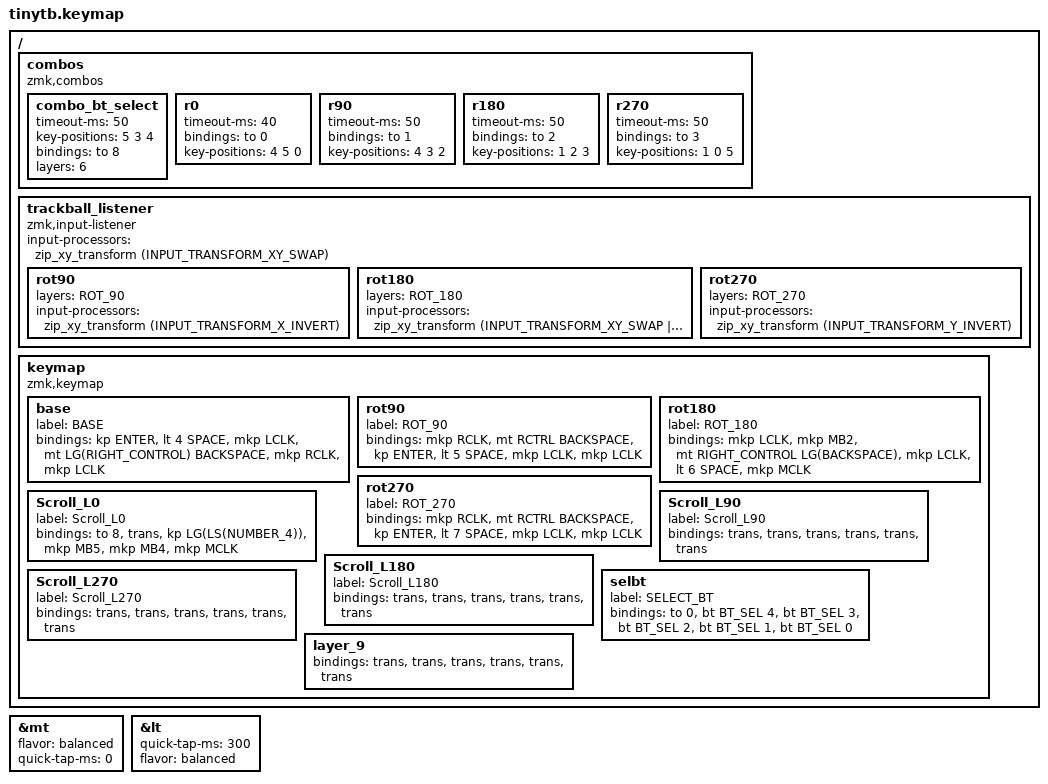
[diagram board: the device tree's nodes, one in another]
#include <input/processors.dtsi>
#include <dt-bindings/zmk/input_transform.h>
#include <zephyr/dt-bindings/input/input-event-codes.h>
#include <dt-bindings/zmk/behaviors.h>
#include <behaviors.dtsi>
#include <dt-bindings/zmk/bt.h>
#include <dt-bindings/zmk/keys.h>
#include <dt-bindings/zmk/pointing.h>

#define SCROLL 1

/* どこかの共通ヘッダの近くに */

#define BASE        0
#define ROT_90      1
#define ROT_180     2
#define ROT_270     3
#define Scroll_L0   4
#define Scroll_L90  5
#define Scroll_L180 6
#define Scroll_L270 7
#define SELECT_BT   8     /* BT設定レイヤー */

&mt {
    flavor = "balanced";
    quick-tap-ms = <0>;
};

&lt {
    quick-tap-ms = <300>;
    flavor = "balanced";
};

/ {
    /* --- コンボ定義 --- */

    combos {
        compatible = "zmk,combos";

        /* 同時押しで 設定レイヤーを開閉（トグル） */

        combo_bt_select {
            timeout-ms = <50>;              /* 反応が鈍ければ少し上げる(例: 60〜80) */
            key-positions = <5 3 4>;        /* ← ここは “1/2/3 キーの物理位置” */
            bindings = <&to 8>;   /* 入る/出るをトグル */
            /* 必要なら layers = <BASE L1 L2>; を付けて適用範囲を絞る */

            layers = <6>;
        };

        r0 {
            timeout-ms = <40>;
            bindings = <&to 0>;
            key-positions = <4 5 0>;
        };

        r90 {
            timeout-ms = <50>;              /* 反応が鈍ければ少し上げる(例: 60〜80) */
            bindings = <&to 1>;
            key-positions = <4 3 2>;
        };

        r180 {
            timeout-ms = <50>;              /* 反応が鈍ければ少し上げる(例: 60〜80) */
            bindings = <&to 2>;     /* ★1秒ホールドで 180 へ */
            key-positions = <1 2 3>;
        };

        r270 {
            timeout-ms = <50>;              /* 反応が鈍ければ少し上げる(例: 60〜80) */
            bindings = <&to 3>;     /* ★1秒ホールドで 270 へ */
            key-positions = <1 0 5>;
        };
    };

    /* 入力プロセッサ（回転設定） */

    trackball_listener: trackball_listener {
        compatible = "zmk,input-listener";
        status = "okay";

        /* 基本(0°) = XY入替 完成済み*/

        input-processors = <&zip_xy_transform (INPUT_TRANSFORM_XY_SWAP)>;

        rot90 {
            layers = <ROT_90>;

            /* 90° = XY入替 + X反転 完成済み */

            input-processors = <&zip_xy_transform (INPUT_TRANSFORM_X_INVERT)>;
        };

        rot180 {
            layers = <ROT_180>;

            /* 180° =XY入替 + Y反転 完成済み */

            input-processors = <&zip_xy_transform (INPUT_TRANSFORM_XY_SWAP | INPUT_TRANSFORM_X_INVERT | INPUT_TRANSFORM_Y_INVERT)>;
        };

        rot270 {
            layers = <ROT_270>;

            /* 270° = Y反転 完成済み */

            input-processors = <&zip_xy_transform (INPUT_TRANSFORM_Y_INVERT)>;
        };
    };

    keymap {
        compatible = "zmk,keymap";

        /* 6キー想定（2×3）: 行ごとに3つずつ並べて6個 */

        base {
            label = "BASE";
            bindings = <
&kp ENTER  &lt 4 SPACE  &mkp LCLK  &mt LG(RIGHT_CONTROL) BACKSPACE  &mkp RCLK  &mkp LCLK
            >;
        };

        /* 回転 */

        rot90 {
            label = "ROT_90";
            bindings = <
&mkp RCLK  &mt RCTRL BACKSPACE  &kp ENTER  &lt 5 SPACE  &mkp LCLK  &mkp LCLK
            >;
        };

        rot180 {
            label = "ROT_180";
            bindings = <
&mkp LCLK  &mkp MB2  &mt RIGHT_CONTROL LG(BACKSPACE)  &mkp LCLK  &lt 6 SPACE  &mkp MCLK
            >;
        };

        rot270 {
            label = "ROT_270";
            bindings = <
&mkp RCLK  &mt RCTRL BACKSPACE  &kp ENTER  &lt 7 SPACE  &mkp LCLK  &mkp LCLK
            >;
        };

        /* スクロール用 */

        Scroll_L0 {
            label = "Scroll_L0 ";
            bindings = <
&to 8  &trans  &kp LG(LS(NUMBER_4))  &mkp MB5  &mkp MB4  &mkp MCLK
            >;
        };

        Scroll_L90 {
            label = "Scroll_L90";
            bindings = <
&trans  &trans  &trans  &trans  &trans  &trans
            >;
        };

        Scroll_L180 {
            label = "Scroll_L180";
            bindings = <
&trans  &trans  &trans  &trans  &trans  &trans
            >;
        };

        Scroll_L270 {
            label = "Scroll_L270";
            bindings = <
&trans  &trans  &trans  &trans  &trans  &trans
            >;
        };

        /* 設定(選択)レイヤー：回転を選んで 6 で確定（閉じる） */

        selbt {
            label = "SELECT_BT";
            bindings = <
&to 0  &bt BT_SEL 4  &bt BT_SEL 3  &bt BT_SEL 2  &bt BT_SEL 1  &bt BT_SEL 0
            >;
        };

        layer_9 {
            bindings = <
&trans  &trans  &trans  &trans  &trans  &trans
            >;
        };
    };
};
